VERSION "ISM"

NS_ :

BS_:

BU_: ISM Vector_XXX

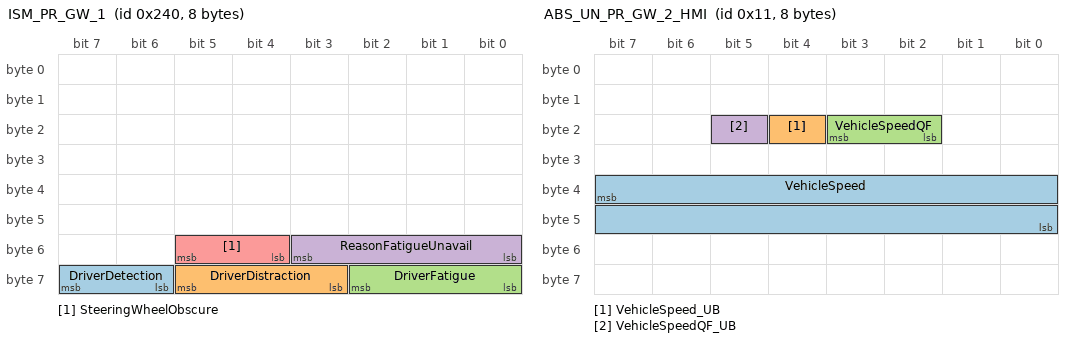
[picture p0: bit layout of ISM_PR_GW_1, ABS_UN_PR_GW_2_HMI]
BO_ 576 ISM_PR_GW_1: 8 ISM
 SG_ DriverDetection : 63|2@0+ (1,0) [0|3] ""  Vector_XXX
 SG_ DriverDistraction : 61|3@0+ (1,0) [0|7] ""  Vector_XXX
 SG_ DriverFatigue : 58|3@0+ (1,0) [0|7] ""  Vector_XXX
 SG_ ReasonFatigueUnavail : 51|4@0+ (1,0) [0|15] ""  Vector_XXX
 SG_ SteeringWheelObscure : 53|2@0+ (1,0) [0|3] ""  Vector_XXX

BO_ 1853 TST_PhysicalRespISM_HMICAN_ASAR: 8 ISM
 SG_ TST_PhysicalRespISM_PDU : 7|64@0+ (1,0) [0|0] ""  Vector_XXX

BO_ 17 ABS_UN_PR_GW_2_HMI: 8 Vector_XXX
 SG_ VehicleSpeed : 39|16@0+ (0.01,0) [0|320] "kph"  ISM
 SG_ VehicleSpeed_UB : 20|1@0+ (1,0) [0|1] ""  ISM
 SG_ VehicleSpeedQF : 19|2@0+ (1,0) [0|3] ""  ISM
 SG_ VehicleSpeedQF_UB : 21|1@0+ (1,0) [0|1] ""  ISM

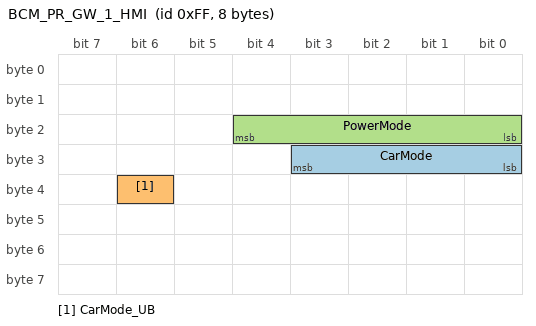
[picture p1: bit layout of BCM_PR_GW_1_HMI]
BO_ 255 BCM_PR_GW_1_HMI: 8 Vector_XXX
 SG_ CarMode : 27|4@0+ (1,0) [6|15] "Unused"  ISM
 SG_ CarMode_UB : 38|1@0+ (1,0) [0|1] ""  ISM
 SG_ PowerMode : 20|5@0+ (1,0) [10|31] "Not Used"  ISM

BO_ 207 DADCA_FR_PR_GW_1_HMI: 8 Vector_XXX
 SG_ AutonomyLevel : 58|3@0+ (1,0) [0|7] ""  ISM

BO_ 1438 HMI_CAN_NodeGWM_NM: 8 Vector_XXX
 SG_ HMI_CAN_GWM_NM_PDU : 7|64@0+ (1,0) [0|0] ""  ISM

BO_ 962 NFSM_FR_PR_GW_B_HMI: 8 Vector_XXX
 SG_ LMActiveFeature : 59|4@0+ (1,0) [0|15] ""  ISM

BO_ 974 NFSM_FR_PR_GW_PASMNVR: 8 Vector_XXX
 SG_ LMParkingType : 42|3@0+ (1,0) [0|7] ""  ISM

BO_ 86 SASM_FR_GW_1_HMI: 8 Vector_XXX
 SG_ SteeringWheelAngle : 31|16@0+ (0.1,-780) [-780|780] "Degrees"  ISM
 SG_ SteeringWheelAngleStatus : 17|2@0+ (1,0) [0|3] ""  ISM

BO_ 2015 TST_FunctionalReq_HMIBus_AUTOSAR: 8 Vector_XXX
 SG_ TST_FunctionalReq_HMI_PDU : 7|64@0+ (1,0) [0|0] ""  ISM

BO_ 1845 TST_PhysicalReqISM_HMICAN_ASAR: 8 Vector_XXX
 SG_ TST_PhysicalReqISM_PDU : 7|64@0+ (1,0) [0|0] ""  ISM

BO_ 1025 VEHCONFIG_400HMI_AutoSAR: 8 Vector_XXX
 SG_ SF_VEHCONFIG_400HMI_AutoSAR_PDU M : 0|8@1+ (1,0) [0|255] ""  ISM
 SG_ CcfGearboxType m2 : 31|8@0+ (1,0) [0|255] ""  ISM
 SG_ CcfVINPart1 m87 : 39|32@0+ (1,0) [0|4294967295] ""  ISM
 SG_ CcfVINPart2 m88 : 15|56@0+ (1,0) [0|7.20575940379279E+016] ""  ISM
 SG_ CcfVINPart3 m89 : 15|48@0+ (1,0) [0|281474976710655] ""  ISM
 SG_ CcfDriverConditionMon m107 : 27|4@0+ (1,0) [0|15] ""  ISM
 SG_ CcfDD00GlobalRealTime m176 : 15|32@0+ (1,0) [0|4294967295] ""  ISM
 SG_ CcfDD02MainECUSupVolts m176 : 47|8@0+ (0.25,0) [0|63.75] "Volts"  ISM
 SG_ CcfDD06PowerModePKT m176 : 52|5@0+ (1,0) [0|31] ""  ISM
 SG_ CcfDD01TotalDistance m177 : 15|24@0+ (1,0) [0|16777215] ""  ISM
 SG_ CcfDD04InCarTemp m177 : 39|8@0+ (1,-40) [-40|215] "Deg C"  ISM
 SG_ CcfDD05OutdoorTemp m177 : 47|8@0+ (1,-40) [-40|215] "Deg C"  ISM

CM_ SG_ 576 DriverDetection "States whether the driver facing camera has detected the presence of a driver.";
CM_ SG_ 576 DriverDistraction "Provides the driver distraction determined by the driver facing camera. This is an internal signal to the Driver Condition Monitoring system and should not be used by any other system.";
CM_ SG_ 576 DriverFatigue "Indicates the fatigue level of the driver.";
CM_ SG_ 576 ReasonFatigueUnavail "Provides the reason why the driver facing camera cannot determine the fatigue level of the driver. This is an internal signal to the Driver Condition Monitoring system and should not be used by any other system.";
CM_ SG_ 576 SteeringWheelObscure "States whether the ability for the driver facing camera to see the driver is blocked by the steering wheel.";
CM_ SG_ 17 VehicleSpeed "Use in conjunction with VehicleSpeedQF. A value of 65535d may also be set under error conditions.

Rear Wheel Drive and AWD Vehicles (Jaguar X150/X250/X351/X152/X760/X260/X761):
---------------------------------------------------------------------------------------
VehicleSpeed is calculated as the average speed of the two driven rear wheels. If one wheel speed sensor fails, VehicleSpeed will use the speed information from the other sensor. Based on a rolling circumference of 2.101m on X150/X250/X351/X152. Based on a rolling circumference of 2.050m on X760. Based on a rolling circumference of 2.000m on X260. Based on a rolling circumference of 2.300m on X761.

Four Wheel Drive Vehicles (LandRover L319/L320/L322/L405/L494/L462):
--------------------------------------------------------------------------------------------
VehicleSpeed is calculated as the average speed of all four wheels. In the case of wheel speed sensor failures, VehicleSpeed will use the speed information from the remaining sensors. ";
CM_ SG_ 17 VehicleSpeedQF "Quality factor for the signal VehicleSpeed. EuCD compliant signal.";
CM_ SG_ 255 CarMode "Information about which Carmode the vehicle is in i.e. Normal, factory etc.
";
CM_ SG_ 255 PowerMode "Information of current PowerMode, reflects the current  state of the Power Mode Superviser

For L538:
The signals PowerModeHS, PowerModeHSQF & PowerModeComp are all with the group PowerModeGrpHS. This grouping is to ensure that the signals are packed within the same frame, they are not treated as a group within the BCM. ";
CM_ SG_ 207 AutonomyLevel "Provides the autonomy level that the vehicle is operating within.";
CM_ SG_ 962 LMActiveFeature "Active Feature Status - System  informs which feature/group of feature is active.";
CM_ SG_ 974 LMParkingType "Maneouvre type Selection Status";
CM_ SG_ 86 SteeringWheelAngle "This signal provides the a measurement of the steering wheel position. The angle is measured as referenced from a 0 degree straight-ahead position. 

- If the steering wheel is rotated clockwise, the measurement decreases.
- If the steering wheel is rotated anti-clockwise, the measurement increases.

On certain vehicle lines fitted with relative angle sensors, the straight-ahead position may have to be 'learned' in each ignition cycle after a brief period of driving. On vehicles fitted with absolute angle sensors, this is not the case.

Depending on the vehicle electrical architecture, the signal may be sourced via the ABS module or direct from the SASM.

The MSB of the signal must be written to the COM layer first (with an offset of zero in wr_bytes() ) and therefore transmitted on the bus first.
Similarly, subscribing modules will receive the MSB of the signal when they call rd_bytes(0).

E.g. wr_bytes(0) = published_signal_MSB;

Subscribed_Signal_MSB = rd_bytes(0);";
CM_ SG_ 86 SteeringWheelAngleStatus "2-bit signal relating to SteeringWheelAngleUnsigned. This flag indicates progress with the Learn Centre Algorithm. This signal will indicate a value of 1 (Centre not learned) at the start of every ignition cycle before the algorithm has had a chance to run. As the algorithm runs to completion, the value will increment to 3. Certain exceptional conditions may cause the algorithm to re-run mid-igntion cycle. A fault with the sensor is indicated by a value of 0.
";
CM_ SG_ 1025 CcfGearboxType "Car Configuration - Gearbox Type

Payload MDF = 0x0247";
CM_ SG_ 1025 CcfVINPart1 "Car Configuration - VIN Part 1

VIN Character 1 (Geographic Area) 
VIN Character 2 (Country) 
VIN Character 3 (Manufacturer) 
VIN Character 4 (Market/Specification) 

Payload MDF = 0x5757, 0x5767, 0x5777, 0x5787
";
CM_ SG_ 1025 CcfVINPart2 "Car Configuration - VIN Part 2

VIN Character 5 (Transmission & Steering) 
VIN Character 6 (Model Range) 
VIN Character 7 (Model Range) 
VIN Character 8 (Emission Control System) 
VIN Character 9 (Check Digit) 
VIN Character 10 (Model Year) 
VIN Character 11 (Assembly Plant & Model Line) 

Payload MDF = 0x0x5827, 0x5837, 0x5847, 0x5857, 0x5867, 0x5877, 0x5887";
CM_ SG_ 1025 CcfVINPart3 "Car Configuration - VIN Part 3

VIN Character 12 (Serial Number 1) 
VIN Character 13 (Serial Number 2) 
VIN Character 14 (Serial Number 3) 
VIN Character 15 (Serial Number 4) 
VIN Character 16 (Serial Number 5) 
VIN Character 17 (Serial Number 6)

Payload MDF = 0x5927,  0x5937, 0x5947, 0x5957, 0x5967, 0x5977
";
CM_ SG_ 1025 CcfDriverConditionMon "CCF Parameter for Driver Condition Monitoring.

MDF - 0x6B43";
CM_ SG_ 1025 CcfDD00GlobalRealTime "Global Identifier   DD00	
ID Name               Global Real Time
Size (Bytes)          4
Type                     Unsigned Numeric
Data Description   As defined in GMRDB

Resolution ref: 1/600  Resolution: 0.001666666667 
Numeric size (bits): 32 
Offset: 0.0 
Minimum value: 0.0  Maximum value: 7158278.825 
Unit: min

(from GMRDB)

MDF 0xB027";
CM_ SG_ 1025 CcfDD02MainECUSupVolts "Global Identifier   DD02
ID Name               Main ECU Supply Voltage
Size (Bytes)          1
Type                     Unsigned Numeric
Data Description   As defined in GMRDB

MDF 0xB067";
CM_ SG_ 1025 CcfDD06PowerModePKT "Global Identifier   DD06
ID Name               Power Mode (PKT1)
Size (Bytes)          1
Type                     Packeted
Data Description   As defined in GMRDB

Parameter Size (bits) Datatype Description   

1 3 State Encoded Power Mode Quality Factor   (NOT USED)
2 5 State Encoded Power Mode   

(from GMRDB)

MDF 0xB074";
CM_ SG_ 1025 CcfDD01TotalDistance "Global Identifier   DD01
ID Name               Total Distance
Size (Bytes)          3
Type                     Unsigned Numeric
Data Description   As defined in GMRDB

Resolution ref: 1  Resolution: 1.0 
Numeric size (bits): 24 
Offset: 0.0 
Minimum value: 0.0  Maximum value: 1.6777215E7 
Unit: km 

MDF 0xB127";
CM_ SG_ 1025 CcfDD04InCarTemp "Global Identifier   DD04
ID Name               In-Car Temperature
Size (Bytes)          1
Type                     Unsigned Numeric
Data Description   As defined in GMRDB

MDF 0xB157";
CM_ SG_ 1025 CcfDD05OutdoorTemp "Global Identifier   DD05
ID Name               Outdoor Temperature
Size (Bytes)          1
Type                     Unsigned Numeric
Data Description   As defined in GMRDB

MDF 0xB167";
BA_DEF_  "Baudrate" FLOAT 1000 1000000;
BA_DEF_ BO_  "GenMsgSendType" ENUM  "cyclic","spontaneous","cyclicIfActive","spontaneousWithDelay","cyclicAndSpontaneous","cyclicAndSpontaneousWithDelay";
BA_DEF_ BO_  "GenMsgCycleTime" FLOAT 0 300000;
BA_DEF_ BO_  "GenMsgStartDelayTime" FLOAT 0 300000;
BA_DEF_ BO_  "GenMsgDelayTime" FLOAT 0 300000;
BA_DEF_ SG_  "GenSigSendType" ENUM  "Cyclic","OnWrite","OnWriteWithRepetition","OnChange","OnChangeWithRepetition","IfActive","IfActiveWithRepetition","NoSigSendType";
BA_DEF_ SG_  "GenSigStartValue" FLOAT -1.79769313486232E+308 1.84467440737096E+019;
BA_DEF_ BU_  "NmAsrNodeIdentifier" INT 1 60;
BA_DEF_  "DBName" STRING ;
BA_DEF_  "BusType" STRING ;
BA_DEF_  "ProtocolType" STRING ;
BA_DEF_DEF_  "Baudrate" 1000;
BA_DEF_DEF_  "GenMsgSendType" "";
BA_DEF_DEF_  "GenMsgCycleTime" 0;
BA_DEF_DEF_  "GenMsgStartDelayTime" 0;
BA_DEF_DEF_  "GenMsgDelayTime" 0;
BA_DEF_DEF_  "GenSigSendType" "Cyclic";
BA_DEF_DEF_  "GenSigStartValue" 0;
BA_DEF_DEF_  "NmAsrNodeIdentifier" 1;
BA_DEF_DEF_  "DBName" "";
BA_DEF_DEF_  "BusType" "";
BA_DEF_DEF_  "ProtocolType" "";
BA_ "Baudrate" 500000;
BA_ "ProtocolType" "CAN";
BA_ "BusType" "CAN";
BA_ "DBName" "ISM";
BA_ "GenMsgCycleTime" BO_ 576 180;
BA_ "GenMsgSendType" BO_ 576 0;
BA_ "GenMsgSendType" BO_ 1853 1;
BA_ "GenMsgDelayTime" BO_ 17 20;
BA_ "GenMsgSendType" BO_ 17 1;
BA_ "GenMsgDelayTime" BO_ 255 50;
BA_ "GenMsgSendType" BO_ 255 1;
BA_ "GenMsgDelayTime" BO_ 207 100;
BA_ "GenMsgSendType" BO_ 207 1;
BA_ "GenMsgDelayTime" BO_ 1438 500;
BA_ "GenMsgSendType" BO_ 1438 1;
BA_ "GenMsgDelayTime" BO_ 962 100;
BA_ "GenMsgSendType" BO_ 962 1;
BA_ "GenMsgDelayTime" BO_ 974 80;
BA_ "GenMsgSendType" BO_ 974 1;
BA_ "GenMsgDelayTime" BO_ 86 20;
BA_ "GenMsgSendType" BO_ 86 1;
BA_ "GenMsgSendType" BO_ 2015 1;
BA_ "GenMsgDelayTime" BO_ 1845 5;
BA_ "GenMsgSendType" BO_ 1845 1;
BA_ "GenMsgDelayTime" BO_ 1025 5;
BA_ "GenMsgSendType" BO_ 1025 1;
BA_ "GenSigStartValue" SG_ 17 VehicleSpeedQF 1;
BA_ "GenSigStartValue" SG_ 86 SteeringWheelAngle 7800;
BA_ "GenSigStartValue" SG_ 86 SteeringWheelAngleStatus 1;
BA_ "GenSigSendType" SG_ 1025 CcfGearboxType 1;
BA_ "GenSigSendType" SG_ 1025 CcfVINPart1 1;
BA_ "GenSigSendType" SG_ 1025 CcfVINPart2 1;
BA_ "GenSigSendType" SG_ 1025 CcfVINPart3 1;
BA_ "GenSigSendType" SG_ 1025 CcfDriverConditionMon 1;
BA_ "GenSigSendType" SG_ 1025 CcfDD00GlobalRealTime 1;
BA_ "GenSigSendType" SG_ 1025 CcfDD02MainECUSupVolts 1;
BA_ "GenSigSendType" SG_ 1025 CcfDD06PowerModePKT 1;
BA_ "GenSigSendType" SG_ 1025 CcfDD01TotalDistance 1;
BA_ "GenSigSendType" SG_ 1025 CcfDD04InCarTemp 1;
BA_ "GenSigSendType" SG_ 1025 CcfDD05OutdoorTemp 1;
VAL_ 576 DriverDetection 0 "Unavailable (Default)" 1 "Not detected" 2 "Detected" 3 "Unused" ;
VAL_ 576 DriverDistraction 0 "Unavailable (Default)" 1 "Unknown" 2 "Not distracted" 3 "Distracted" 4 "Unused4" 5 "Unused5" 6 "Unused6" 7 "Unused7" ;
VAL_ 576 DriverFatigue 0 "Unavailable" 1 "Unknown" 2 "Alert" 3 "Fatigued" 4 "Highly Fatigued" 5 "Suspected Unresponsive" 6 "Confirmed Unresponsive" 7 "Not Used" ;
VAL_ 576 ReasonFatigueUnavail 0 "None (Default)" 1 "System failure" 2 "Eyes not visible due to IR blocking glasses" 3 "Eyes not visible due to head rotation" 4 "Eyes not visible due to steering wheel rim" 5 "Eyes not visible due to misc cause" 6 "Reserved" 7 "Reserved" 8 "Reserved" 9 "Reserved" 10 "Reserved" 11 "Reserved" 12 "Reserved" 13 "Reserved" 14 "Reserved" 15 "Reserved" ;
VAL_ 576 SteeringWheelObscure 0 "Unavailable (Default)" 1 "FALSE (camera not blocked)" 2 "TRUE (camera blocked)" 3 "Reserved" ;
VAL_ 17 VehicleSpeedQF 0 "The accuracy of the data is undefinable" 1 "Data is temporarily undefinable, evaluation in progress" 2 "The accuracy of the data is not within specification" 3 "The data is calculated with the specified accuracy" ;
VAL_ 255 CarMode 0 "Normal" 1 "Factory" 2 "Unused" 3 "Transport" 4 "Unused" 5 "Crash" ;
VAL_ 255 PowerMode 0 "KeyOut" 1 "KeyRecentlyOut" 2 "KeyApproved_0" 3 "PostAccessory_0" 4 "Accessory_1" 5 "PostIgnition_1" 6 "IgnitionOn_2" 7 "Running_2" 8 "(Not used)" 9 "Crank_3" ;
VAL_ 207 AutonomyLevel 0 "Unavailable (Default)" 1 "Level 0" 2 "Level 1" 3 "Level 2" 4 "Level 3" 5 "Level 4" 6 "Level 5" 7 "Reserved" ;
VAL_ 962 LMActiveFeature 0 " No Feature Active" 1 "Parking Feature" 2 "Remote Control Drive" 3 "Wireless Charging Alignment" 4 "LSAEB" 5 "Tow Assist" 6 "RESERVED10" 7 "RESERVED9" 8 "RESERVED8" 9 "RESERVED7" 10 "RESERVED6" 11 "RESERVED5" 12 "RESERVED4" 13 "RESERVED3" 14 "RESERVED2" 15 "RESERVED1" ;
VAL_ 974 LMParkingType 0 "None" 1 "Assisted" 2 "Automated" 3 "Remote" 4 "PushPull" 5 "Longitudinal Adjust" 6 "RESERVED2" 7 "RESERVED1" ;
VAL_ 86 SteeringWheelAngle 65535 "Error Marker" ;
VAL_ 86 SteeringWheelAngleStatus 0 "Fault condition" 1 "Steering angle not known or not initialised" 2 "Centre not confirmed (unused on L405)" 3 "Centre confirmed" ;
VAL_ 1025 CcfGearboxType 0 "Undefined" 1 "Manual gearbox" 2 "Automatic gearbox" 3 "Powershift Gearbox" 255 "Error" ;
VAL_ 1025 CcfDriverConditionMon 0 "Not Supported" 1 "Not Fitted" 2 "Variant A: Driver fatigue warning" 3 "Variant B: Driver fatigue warning & Rest area assistance" 4 "Variant C: Driver fatigue warning, Rest area assistance & Distraction signal" 5 "Variant D: Driver fatigue warning, Rest area assistance, Distraction monitoring & Unresponsiveness Warning" 15 "Error" ;
SIG_GROUP_ 576 DCMCoreGroup 1 : DriverDetection DriverDistraction DriverFatigue ReasonFatigueUnavail SteeringWheelObscure;
SIG_GROUP_ 1025 CCFPayload0xB0 1 : CcfDD00GlobalRealTime CcfDD02MainECUSupVolts CcfDD06PowerModePKT;
SIG_GROUP_ 1025 CCFPayload0xB1 1 : CcfDD01TotalDistance CcfDD04InCarTemp CcfDD05OutdoorTemp;
